AUTOSAR XML (schema 4-3-1)
standard types defined: uint8, uint8_DataConstr
package /ComponentTypes
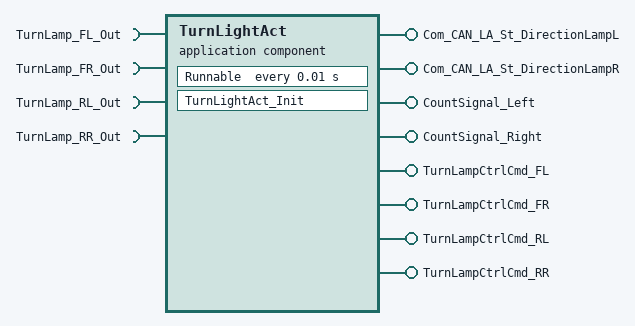
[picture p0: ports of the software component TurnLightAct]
  application sw component type TurnLightAct
    4 x require port:
      TurnLamp_FL_Out: nonqueued-receiver-com-spec{data-element=TurnLamp_FL_Out/Signal, init-value=ComSpec2d66f748_aeef2827df3ffc31:0}, required-interface=TurnLamp_FL_Out
      TurnLamp_FR_Out: nonqueued-receiver-com-spec{data-element=TurnLamp_FR_Out/Signal, init-value=ComSpec470147e4_089f8f4a807e6411:0}, required-interface=TurnLamp_FR_Out
      TurnLamp_RL_Out: nonqueued-receiver-com-spec{data-element=TurnLamp_RL_Out/Signal, init-value=ComSpecedc54774_9f1c9f596490c4a1:0}, required-interface=TurnLamp_RL_Out
      TurnLamp_RR_Out: nonqueued-receiver-com-spec{data-element=TurnLamp_RR_Out/Signal, init-value=ComSpecaa3af8a7_64e528c233ba08a1:0}, required-interface=TurnLamp_RR_Out
    8 x provide port:
      Com_CAN_LA_St_DirectionLampL: nonqueued-sender-com-spec{data-element=Com_CAN_LA_St_DirectionLampL/Signal, init-value=ComSpece258038b_ca763e803bafbb12:0}, provided-interface=Com_CAN_LA_St_DirectionLampL
      Com_CAN_LA_St_DirectionLampR: nonqueued-sender-com-spec{data-element=Com_CAN_LA_St_DirectionLampR/Signal, init-value=ComSpecba48c184_b30c280981f0e770:0}, provided-interface=Com_CAN_LA_St_DirectionLampR
      CountSignal_Left: nonqueued-sender-com-spec{data-element=CountSignal_Left/Signal, init-value=ComSpec04e3352f_3cca41b60bd9ee70:0}, provided-interface=CountSignal_Left
      CountSignal_Right: nonqueued-sender-com-spec{data-element=CountSignal_Right/Signal, init-value=ComSpec808fd11f_5a3e66881473edee:0}, provided-interface=CountSignal_Right
      TurnLampCtrlCmd_FL: nonqueued-sender-com-spec{data-element=TurnLampCtrlCmd_FL/Signal, init-value=ComSpecabaef78a_ca18bbbcd54f00ab:0}, provided-interface=TurnLampCtrlCmd_FL
      TurnLampCtrlCmd_FR: nonqueued-sender-com-spec{data-element=TurnLampCtrlCmd_FR/Signal, init-value=ComSpec60809762_db4479dad02748ea:0}, provided-interface=TurnLampCtrlCmd_FR
      TurnLampCtrlCmd_RL: nonqueued-sender-com-spec{data-element=TurnLampCtrlCmd_RL/Signal, init-value=ComSpecd7ae45a8_221b391a086dfbfe:0}, provided-interface=TurnLampCtrlCmd_RL
      TurnLampCtrlCmd_RR: nonqueued-sender-com-spec{data-element=TurnLampCtrlCmd_RR/Signal, init-value=ComSpec52a4c933_54e4502d714372d7:0}, provided-interface=TurnLampCtrlCmd_RR
    behavior TurnLightAct_InternalBehavior: handle-termination-and-restart=NO-SUPPORT
      timing event TMT_Runnable: start-on-event=Runnable, period=0.01
      runnable Runnable
        data-receive-point-by-arguments:
          4 x access:
            IN_TurnLamp_FL_Out_Signal: accessed-variable=TurnLamp_FL_Out.Signal
            IN_TurnLamp_FR_Out_Signal: accessed-variable=TurnLamp_FR_Out.Signal
            IN_TurnLamp_RL_Out_Signal: accessed-variable=TurnLamp_RL_Out.Signal
            IN_TurnLamp_RR_Out_Signal: accessed-variable=TurnLamp_RR_Out.Signal
        data-send-points:
          8 x access:
            OUT_Com_CAN_LA_St_DirectionLampL_Signal: accessed-variable=Com_CAN_LA_St_DirectionLampL.Signal
            OUT_Com_CAN_LA_St_DirectionLampR_Signal: accessed-variable=Com_CAN_LA_St_DirectionLampR.Signal
            OUT_CountSignal_Left_Signal: accessed-variable=CountSignal_Left.Signal
            OUT_CountSignal_Right_Signal: accessed-variable=CountSignal_Right.Signal
            OUT_TurnLampCtrlCmd_FL_Signal: accessed-variable=TurnLampCtrlCmd_FL.Signal
            OUT_TurnLampCtrlCmd_FR_Signal: accessed-variable=TurnLampCtrlCmd_FR.Signal
            OUT_TurnLampCtrlCmd_RL_Signal: accessed-variable=TurnLampCtrlCmd_RL.Signal
            OUT_TurnLampCtrlCmd_RR_Signal: accessed-variable=TurnLampCtrlCmd_RR.Signal
      runnable TurnLightAct_Init
        data-send-points:
          8 x access:
            OUT_Com_CAN_LA_St_DirectionLampL_Signal: accessed-variable=Com_CAN_LA_St_DirectionLampL.Signal
            OUT_Com_CAN_LA_St_DirectionLampR_Signal: accessed-variable=Com_CAN_LA_St_DirectionLampR.Signal
            OUT_CountSignal_Left_Signal: accessed-variable=CountSignal_Left.Signal
            OUT_CountSignal_Right_Signal: accessed-variable=CountSignal_Right.Signal
            OUT_TurnLampCtrlCmd_FL_Signal: accessed-variable=TurnLampCtrlCmd_FL.Signal
            OUT_TurnLampCtrlCmd_FR_Signal: accessed-variable=TurnLampCtrlCmd_FR.Signal
            OUT_TurnLampCtrlCmd_RL_Signal: accessed-variable=TurnLampCtrlCmd_RL.Signal
            OUT_TurnLampCtrlCmd_RR_Signal: accessed-variable=TurnLampCtrlCmd_RR.Signal
package /PortInterfaces
  12 x sender receiver interface:
    Com_CAN_LA_St_DirectionLampL: invalidation-policy{data-element=Com_CAN_LA_St_DirectionLampL/Signal, handle-invalid=DONT-INVALIDATE}
      data Signal: category=VALUE, type=uint8
    Com_CAN_LA_St_DirectionLampR: invalidation-policy{data-element=Com_CAN_LA_St_DirectionLampR/Signal, handle-invalid=DONT-INVALIDATE}
      data Signal: category=VALUE, type=uint8
    CountSignal_Left: invalidation-policy{data-element=CountSignal_Left/Signal, handle-invalid=DONT-INVALIDATE}
      data Signal: category=VALUE, type=uint8
    CountSignal_Right: invalidation-policy{data-element=CountSignal_Right/Signal, handle-invalid=DONT-INVALIDATE}
      data Signal: category=VALUE, type=uint8
    TurnLamp_FL_Out: invalidation-policy{data-element=TurnLamp_FL_Out/Signal, handle-invalid=DONT-INVALIDATE}
      data Signal: category=VALUE, type=uint8
    TurnLamp_FR_Out: invalidation-policy{data-element=TurnLamp_FR_Out/Signal, handle-invalid=DONT-INVALIDATE}
      data Signal: category=VALUE, type=uint8
    TurnLamp_RL_Out: invalidation-policy{data-element=TurnLamp_RL_Out/Signal, handle-invalid=DONT-INVALIDATE}
      data Signal: category=VALUE, type=uint8
    TurnLamp_RR_Out: invalidation-policy{data-element=TurnLamp_RR_Out/Signal, handle-invalid=DONT-INVALIDATE}
      data Signal: category=VALUE, type=uint8
    TurnLampCtrlCmd_FL: invalidation-policy{data-element=TurnLampCtrlCmd_FL/Signal, handle-invalid=DONT-INVALIDATE}
      data Signal: category=VALUE, type=uint8
    TurnLampCtrlCmd_FR: invalidation-policy{data-element=TurnLampCtrlCmd_FR/Signal, handle-invalid=DONT-INVALIDATE}
      data Signal: category=VALUE, type=uint8
    TurnLampCtrlCmd_RL: invalidation-policy{data-element=TurnLampCtrlCmd_RL/Signal, handle-invalid=DONT-INVALIDATE}
      data Signal: category=VALUE, type=uint8
    TurnLampCtrlCmd_RR: invalidation-policy{data-element=TurnLampCtrlCmd_RR/Signal, handle-invalid=DONT-INVALIDATE}
      data Signal: category=VALUE, type=uint8
